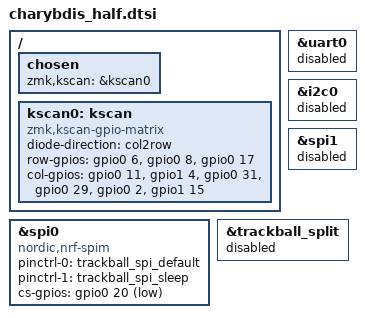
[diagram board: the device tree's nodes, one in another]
#include <zephyr/dt-bindings/gpio/gpio.h>
#include <zephyr/dt-bindings/pinctrl/nrf-pinctrl.h>
#include "charybdis.dtsi"
#include "split_input_common.dtsi"

/ {
    chosen {
        zmk,kscan = &kscan0;
    };

    kscan0: kscan {
        compatible = "zmk,kscan-gpio-matrix";
        diode-direction = "col2row";
        row-gpios = <&gpio0 6 (GPIO_ACTIVE_HIGH | GPIO_PULL_DOWN)>,
                    <&gpio0 8 (GPIO_ACTIVE_HIGH | GPIO_PULL_DOWN)>,
                    <&gpio0 17 (GPIO_ACTIVE_HIGH | GPIO_PULL_DOWN)>;
        col-gpios = <&gpio0 11 GPIO_ACTIVE_HIGH>,
                    <&gpio1 4 GPIO_ACTIVE_HIGH>,
                    <&gpio0 31 GPIO_ACTIVE_HIGH>,
                    <&gpio0 29 GPIO_ACTIVE_HIGH>,
                    <&gpio0 2 GPIO_ACTIVE_HIGH>,
                    <&gpio1 15 GPIO_ACTIVE_HIGH>;
    };
};

// These board functions overlap the matrix or trackball pins.
&uart0 {
    status = "disabled";
};

&i2c0 {
    status = "disabled";
};

&spi1 {
    status = "disabled";
};

&spi0 {
    compatible = "nordic,nrf-spim";
    status = "okay";
    pinctrl-0 = <&trackball_spi_default>;
    pinctrl-1 = <&trackball_spi_sleep>;
    pinctrl-names = "default", "sleep";
    cs-gpios = <&gpio0 20 GPIO_ACTIVE_LOW>;
};

&trackball_split {
    status = "disabled";
};
